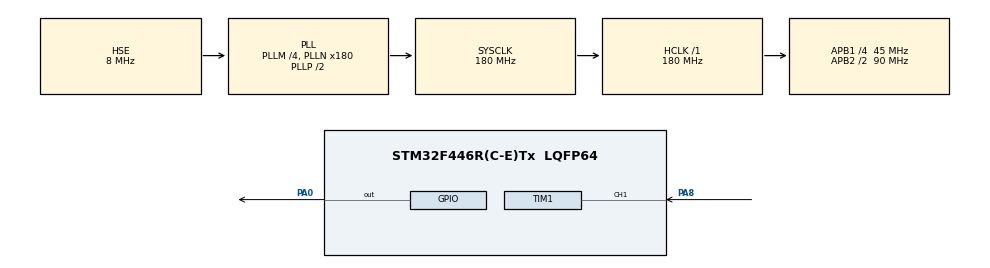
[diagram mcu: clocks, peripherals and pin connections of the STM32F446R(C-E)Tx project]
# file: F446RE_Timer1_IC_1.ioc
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Mcu.Family=STM32F4
Mcu.Name=STM32F446R(C-E)Tx
Mcu.Package=LQFP64
NVIC.PriorityGroup=NVIC_PRIORITYGROUP_0
NVIC.TIM1_BRK_TIM9_IRQn=true\:0\:0\:false\:false\:true\:true\:true\:true
NVIC.TIM1_CC_IRQn=true\:0\:0\:false\:false\:true\:true\:true\:true
NVIC.TIM1_TRG_COM_TIM11_IRQn=true\:0\:0\:false\:false\:true\:true\:true\:true
NVIC.TIM1_UP_TIM10_IRQn=true\:0\:0\:false\:false\:true\:true\:true\:true
PA0-WKUP.Signal=GPIO_Output
PA8.Signal=S_TIM1_CH1
PH0-OSC_IN.Mode=HSE-External-Clock-Source
PH0-OSC_IN.Signal=RCC_OSC_IN
PH1-OSC_OUT.Mode=HSE-External-Clock-Source
PH1-OSC_OUT.Signal=RCC_OSC_OUT
ProjectManager.HeapSize=0x200
ProjectManager.StackSize=0x400
ProjectManager.TargetToolchain=STM32CubeIDE
RCC.48MHZClocksFreq_Value=84000000
RCC.AHBFreq_Value=180000000
RCC.APB1CLKDivider=RCC_HCLK_DIV4
RCC.APB1Freq_Value=45000000
RCC.APB1TimFreq_Value=90000000
RCC.APB2CLKDivider=RCC_HCLK_DIV2
RCC.APB2Freq_Value=90000000
RCC.APB2TimFreq_Value=180000000
RCC.CortexFreq_Value=180000000
RCC.FLatency-AdvancedSettings=FLASH_LATENCY_5
RCC.HCLKFreq_Value=180000000
RCC.HSE_VALUE=8000000
RCC.HSI_VALUE=16000000
RCC.PLLM=4
RCC.PLLN=180
RCC.PLLSourceVirtual=RCC_PLLSOURCE_HSE
RCC.SYSCLKFreq_VALUE=180000000
RCC.SYSCLKSource=RCC_SYSCLKSOURCE_PLLCLK
RCC.USBFreq_Value=180000000
RCC.VCOOutputFreq_Value=360000000
SH.S_TIM1_CH1.0=TIM1_CH1,Input_Capture1_from_TI1
TIM1.Channel-Input_Capture1_from_TI1=TIM_CHANNEL_1
TIM1.ICPrescaler-Input_Capture1_from_TI1=TIM_ICPSC_DIV2
VP_TIM1_VS_ClockSourceINT.Mode=Internal
board=NUCLEO-F446RE

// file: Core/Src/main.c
/* USER CODE BEGIN Header */
/**
  ******************************************************************************
  * @file           : main.c
  * @brief          : Main program body
  ******************************************************************************
  * @attention
  *
  * Copyright (c) 2024 STMicroelectronics.
  * All rights reserved.
  *
  * This software is licensed under terms that can be found in the LICENSE file
  * in the root directory of this software component.
  * If no LICENSE file comes with this software, it is provided AS-IS.
  *
  ******************************************************************************
  */
/* USER CODE END Header */
#include "main.h"

TIM_HandleTypeDef htim1;

/* USER CODE BEGIN PV */
volatile uint16_t lastCaptured = 0;
volatile uint16_t capturevalue = 0;
volatile uint16_t overFlowCount = 0;
volatile uint16_t diff = 0;

/* USER CODE END PV */

void SystemClock_Config(void);
static void MX_GPIO_Init(void);
static void MX_TIM1_Init(void);

/* USER CODE BEGIN 0 */
void HAL_TIM_IC_CaptureCallback(TIM_HandleTypeDef *htim)
{
	if(htim->Channel == HAL_TIM_ACTIVE_CHANNEL_1)
	{
		capturevalue = HAL_TIM_ReadCapturedValue(htim, TIM_CHANNEL_1);
		if(capturevalue >= lastCaptured)
		{
			diff = capturevalue - lastCaptured;
			lastCaptured = capturevalue;
		}
		else
		{
			diff = (0xffff-lastCaptured) + capturevalue + 1;
			lastCaptured = capturevalue;
		}
	}
}
/* USER CODE END 0 */

int main(void)
{

  /* MCU Configuration--------------------------------------------------------*/

  /* Reset of all peripherals, Initializes the Flash interface and the Systick. */
  HAL_Init();

  /* Configure the system clock */
  SystemClock_Config();

  /* Initialize all configured peripherals */
  MX_GPIO_Init();
  MX_TIM1_Init();
  /* USER CODE BEGIN 2 */
  HAL_TIM_IC_Start_IT(&htim1, TIM_CHANNEL_1);
  /* USER CODE END 2 */

  /* Infinite loop */
  /* USER CODE BEGIN WHILE */
  while (1)
  {
	  HAL_GPIO_TogglePin(GPIOA, GPIO_PIN_0);
	  HAL_Delay(100);
    /* USER CODE END WHILE */

  }
}

void SystemClock_Config(void)
{
  RCC_OscInitTypeDef RCC_OscInitStruct = {0};
  RCC_ClkInitTypeDef RCC_ClkInitStruct = {0};

  /** Configure the main internal regulator output voltage
  */
  __HAL_RCC_PWR_CLK_ENABLE();
  __HAL_PWR_VOLTAGESCALING_CONFIG(PWR_REGULATOR_VOLTAGE_SCALE1);

  /** Initializes the RCC Oscillators according to the specified parameters
  * in the RCC_OscInitTypeDef structure.
  */
  RCC_OscInitStruct.OscillatorType = RCC_OSCILLATORTYPE_HSE;
  RCC_OscInitStruct.HSEState = RCC_HSE_BYPASS;
  RCC_OscInitStruct.PLL.PLLState = RCC_PLL_ON;
  RCC_OscInitStruct.PLL.PLLSource = RCC_PLLSOURCE_HSE;
  RCC_OscInitStruct.PLL.PLLM = 4;
  RCC_OscInitStruct.PLL.PLLN = 180;
  RCC_OscInitStruct.PLL.PLLP = RCC_PLLP_DIV2;
  RCC_OscInitStruct.PLL.PLLQ = 2;
  RCC_OscInitStruct.PLL.PLLR = 2;
  if (HAL_RCC_OscConfig(&RCC_OscInitStruct) != HAL_OK)
  {
    Error_Handler();
  }

  /** Activate the Over-Drive mode
  */
  if (HAL_PWREx_EnableOverDrive() != HAL_OK)
  {
    Error_Handler();
  }

  /** Initializes the CPU, AHB and APB buses clocks
  */
  RCC_ClkInitStruct.ClockType = RCC_CLOCKTYPE_HCLK|RCC_CLOCKTYPE_SYSCLK
                              |RCC_CLOCKTYPE_PCLK1|RCC_CLOCKTYPE_PCLK2;
  RCC_ClkInitStruct.SYSCLKSource = RCC_SYSCLKSOURCE_PLLCLK;
  RCC_ClkInitStruct.AHBCLKDivider = RCC_SYSCLK_DIV1;
  RCC_ClkInitStruct.APB1CLKDivider = RCC_HCLK_DIV4;
  RCC_ClkInitStruct.APB2CLKDivider = RCC_HCLK_DIV2;

  if (HAL_RCC_ClockConfig(&RCC_ClkInitStruct, FLASH_LATENCY_5) != HAL_OK)
  {
    Error_Handler();
  }
}

static void MX_TIM1_Init(void)
{

  TIM_ClockConfigTypeDef sClockSourceConfig = {0};
  TIM_MasterConfigTypeDef sMasterConfig = {0};
  TIM_IC_InitTypeDef sConfigIC = {0};

  htim1.Instance = TIM1;
  htim1.Init.Prescaler = 180-1;
  htim1.Init.CounterMode = TIM_COUNTERMODE_UP;
  htim1.Init.Period = 65536-1;
  htim1.Init.ClockDivision = TIM_CLOCKDIVISION_DIV1;
  htim1.Init.RepetitionCounter = 0;
  htim1.Init.AutoReloadPreload = TIM_AUTORELOAD_PRELOAD_DISABLE;
  if (HAL_TIM_Base_Init(&htim1) != HAL_OK)
  {
    Error_Handler();
  }
  sClockSourceConfig.ClockSource = TIM_CLOCKSOURCE_INTERNAL;
  if (HAL_TIM_ConfigClockSource(&htim1, &sClockSourceConfig) != HAL_OK)
  {
    Error_Handler();
  }
  if (HAL_TIM_IC_Init(&htim1) != HAL_OK)
  {
    Error_Handler();
  }
  sMasterConfig.MasterOutputTrigger = TIM_TRGO_RESET;
  sMasterConfig.MasterSlaveMode = TIM_MASTERSLAVEMODE_DISABLE;
  if (HAL_TIMEx_MasterConfigSynchronization(&htim1, &sMasterConfig) != HAL_OK)
  {
    Error_Handler();
  }
  sConfigIC.ICPolarity = TIM_INPUTCHANNELPOLARITY_RISING;
  sConfigIC.ICSelection = TIM_ICSELECTION_DIRECTTI;
  sConfigIC.ICPrescaler = TIM_ICPSC_DIV2;
  sConfigIC.ICFilter = 0;
  if (HAL_TIM_IC_ConfigChannel(&htim1, &sConfigIC, TIM_CHANNEL_1) != HAL_OK)
  {
    Error_Handler();
  }

}

static void MX_GPIO_Init(void)
{
  GPIO_InitTypeDef GPIO_InitStruct = {0};

  /* GPIO Ports Clock Enable */
  __HAL_RCC_GPIOH_CLK_ENABLE();
  __HAL_RCC_GPIOA_CLK_ENABLE();

  /*Configure GPIO pin Output Level */
  HAL_GPIO_WritePin(GPIOA, GPIO_PIN_0, GPIO_PIN_RESET);

  /*Configure GPIO pin : PA0 */
  GPIO_InitStruct.Pin = GPIO_PIN_0;
  GPIO_InitStruct.Mode = GPIO_MODE_OUTPUT_PP;
  GPIO_InitStruct.Pull = GPIO_NOPULL;
  GPIO_InitStruct.Speed = GPIO_SPEED_FREQ_LOW;
  HAL_GPIO_Init(GPIOA, &GPIO_InitStruct);

}

void Error_Handler(void)
{
  __disable_irq();
  while (1)
  {
  }
}
